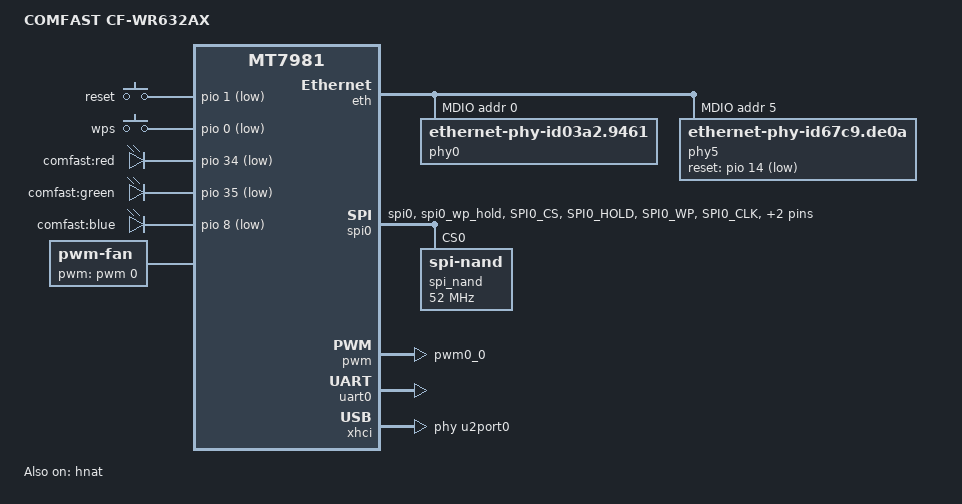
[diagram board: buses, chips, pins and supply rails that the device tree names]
// SPDX-License-Identifier: GPL-2.0-or-later OR MIT
/dts-v1/;

#include "mt7981.dtsi"
#include <dt-bindings/input/input.h>

/ {
	model = "COMFAST CF-WR632AX";
	compatible = "comfast,cf-wr632ax", "mediatek,mt7981";

	aliases {
		label-mac-device = &gmac0;
		led-boot = &led_red;
		led-failsafe = &led_red;
		led-running = &led_green;
		led-upgrade = &led_blue;
	};

	chosen {
		bootargs = "console=ttyS0,115200n1 loglevel=8 \
			    earlycon=uart8250,mmio32,0x11002000";
	};

	gpio-keys {
		compatible = "gpio-keys";

		reset {
			label = "reset";
			linux,code = <KEY_RESTART>;
			gpios = <&pio 1 GPIO_ACTIVE_LOW>;
			debounce-interval = <10>;
		};

		wps {
			label = "wps";
			linux,code = <KEY_WPS_BUTTON>;
			gpios = <&pio 0 GPIO_ACTIVE_LOW>;
			debounce-interval = <10>;
		};
	};

	leds {
		compatible = "gpio-leds";

		led_red: led@0 {
			label = "comfast:red";
			gpios = <&pio 34 GPIO_ACTIVE_LOW>;
		};

		led_green: led@1 {
			label = "comfast:green";
			gpios = <&pio 35 GPIO_ACTIVE_LOW>;
		};

		led_blue: led@2 {
			label = "comfast:blue";
			gpios = <&pio 8 GPIO_ACTIVE_LOW>;
		};
	};

	nmbm_spim_nand {
		compatible = "generic,nmbm";
		#address-cells = <1>;
		#size-cells = <1>;
		lower-mtd-device = <&spi_nand>;
		max-reserved-blocks = <32>;
		forced-create;

		partitions {
			compatible = "fixed-partitions";
			#address-cells = <1>;
			#size-cells = <1>;

			partition@0 {
				label = "BL2";
				reg = <0x0000000 0x0100000>;
			};

			partition@100000 {
				label = "u-boot-env";
				reg = <0x0100000 0x0080000>;
			};

			partition@180000 {
				label = "Factory";
				reg = <0x0180000 0x0200000>;
			};

			partition@380000 {
				label = "FIP";
				reg = <0x0380000 0x0200000>;
			};

			partition@580000 {
				label = "ubi";
				reg = <0x0580000 0x7200000>;
			};
		};
	};

	pwm-fan {
		compatible = "pwm-fan";
		#cooling-cells = <2>;
		pwms = <&pwm 0 10000>;
		cooling-levels = <0 26 51 77 102 128 153 179 204 230 255>;
		status = "okay";
	};
};

&eth {
	status = "okay";

	gmac0: mac@0 {
		compatible = "mediatek,eth-mac";
		reg = <0>;
		phy-mode = "2500base-x";

		fixed-link {
			speed = <2500>;
			full-duplex;
			pause;
		};
	};

	gmac1: mac@1 {
		compatible = "mediatek,eth-mac";
		reg = <1>;
		phy-mode = "gmii";
		phy-handle = <&phy0>;
	};

	mdio: mdio-bus {
		#address-cells = <1>;
		#size-cells = <0>;

		phy0: phy@0 {
			compatible = "ethernet-phy-id03a2.9461";
			reg = <0>;
			nvmem-cells = <&phy_calibration>;
			nvmem-cell-names = "phy-cal-data";
		};

		phy5: phy@5 {
			compatible = "ethernet-phy-id67c9.de0a";
			reg = <5>;
			reset-gpios = <&pio 14 GPIO_ACTIVE_LOW>;
			reset-assert-us = <600>;
			reset-deassert-us = <20000>;
			max-speed = <2500>;
			phy-mode = "2500base-x";
		};
	};
};

&hnat {
	mtketh-wan = "eth1";
	mtketh-lan = "eth0";
	mtketh-ppd = "eth0";
	mtketh-max-gmac = <2>;
	mtketh-ppe-num = <2>;
	status = "okay";
};

&spi0 {
	pinctrl-names = "default";
	pinctrl-0 = <&spi0_flash_pins>;
	status = "okay";

	spi_nand: spi_nand@0 {
		compatible = "spi-nand";
		#address-cells = <1>;
		#size-cells = <1>;
		reg = <0>;
		spi-max-frequency = <52000000>;
		spi-tx-bus-width = <4>;
		spi-rx-bus-width = <4>;
	};
};

&pio {
	pwm0_pin: pwm0-pin-g0 {
		mux {
			function = "pwm";
			groups = "pwm0_0";
		};
	};

	spi0_flash_pins: spi0-pins {
		mux {
			function = "spi";
			groups = "spi0", "spi0_wp_hold";
		};

		conf-pu {
			pins = "SPI0_CS", "SPI0_HOLD", "SPI0_WP";
			drive-strength = <4>;
			bias-pull-up;
		};

		conf-pd {
			pins = "SPI0_CLK", "SPI0_MOSI", "SPI0_MISO";
			drive-strength = <4>;
			bias-pull-down;
		};
	};
};

&pwm {
	pinctrl-names = "default";
	pinctrl-0 = <&pwm0_pin>;
	status = "okay";
};

&uart0 {
	status = "okay";
};

&xhci {
	mediatek,u3p-dis-msk = <0x0>;
	phys = <&u2port0 PHY_TYPE_USB2>, <&u3port0 PHY_TYPE_USB3>;
	status = "okay";
};
